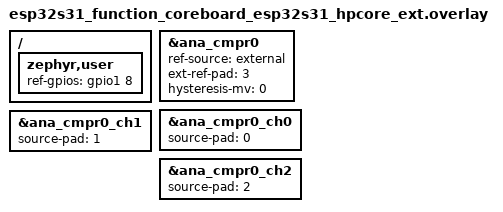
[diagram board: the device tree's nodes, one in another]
/*
 * Copyright (c) 2026 Espressif Systems (Shanghai) Co., Ltd.
 *
 * SPDX-License-Identifier: Apache-2.0
 */

#include <zephyr/dt-bindings/gpio/gpio.h>

/ {
	zephyr,user {
		ref-gpios = <&gpio1 8 GPIO_ACTIVE_HIGH>; /* GPIO40 */
	};
};

&ana_cmpr0 {
	ref-source = "external";
	ext-ref-pad = <3>;
	hysteresis-mv = <0>;
};

&ana_cmpr0_ch0 {
	source-pad = <0>;
	status = "okay";
};

&ana_cmpr0_ch1 {
	source-pad = <1>;
	status = "okay";
};

&ana_cmpr0_ch2 {
	source-pad = <2>;
	status = "okay";
};
